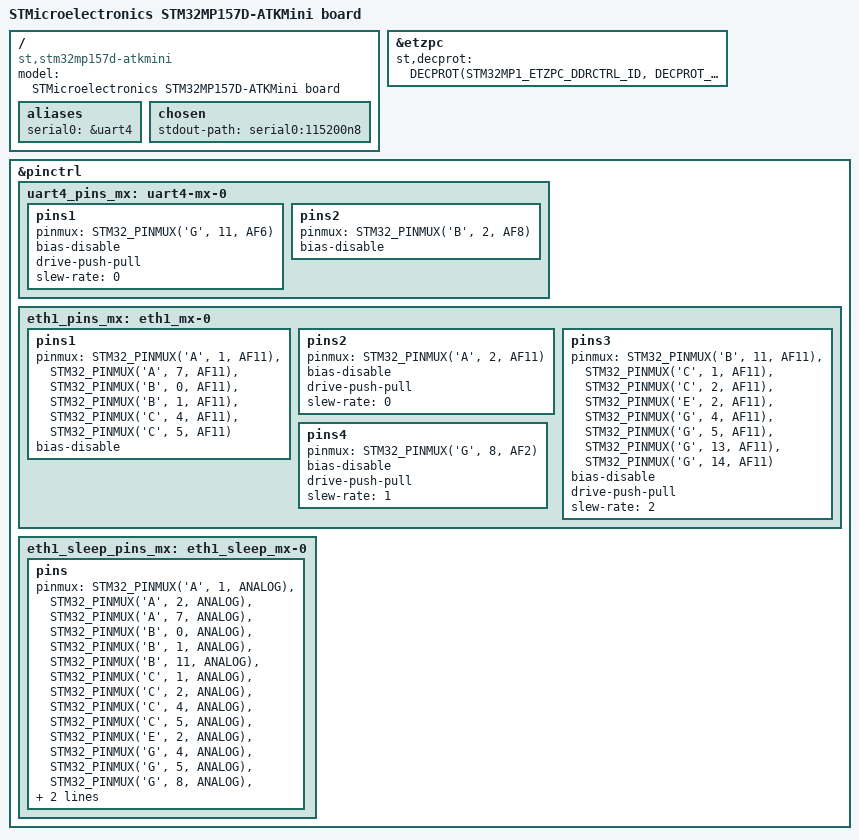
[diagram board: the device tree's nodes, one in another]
// SPDX-License-Identifier: (GPL-2.0+ OR BSD-3-Clause)
/*
 * Copyright (C) STMicroelectronics 2019 - All Rights Reserved
 * Author: Alexandre Torgue <alexandre.torgue@st.com> for STMicroelectronics.
 */
/dts-v1/;

#include "stm32mp157.dtsi"
#include "stm32mp15xd.dtsi"
#include "stm32mp15-pinctrl.dtsi"
#include "stm32mp15xxaa-pinctrl.dtsi"
#include "stm32mp157d-atkmini.dtsi"
#include <dt-bindings/soc/st,stm32-etzpc.h>

/ {
	model = "STMicroelectronics STM32MP157D-ATKMini board";
	compatible = "st,stm32mp157d-atkmini", "st,stm32mp157";

	aliases {
		serial0 = &uart4;
	};

	chosen {
		stdout-path = "serial0:115200n8";
	};
};

&etzpc {
	st,decprot = <
		/*"NS_R S_W" peripherals*/
		DECPROT(STM32MP1_ETZPC_DDRCTRL_ID, DECPROT_NS_R_S_W, DECPROT_LOCK)
		DECPROT(STM32MP1_ETZPC_DDRPHYC_ID, DECPROT_NS_R_S_W, DECPROT_LOCK)
		/*"Non Secured" peripherals*/
		DECPROT(STM32MP1_ETZPC_DMA1_ID, DECPROT_NS_RW, DECPROT_UNLOCK)
		DECPROT(STM32MP1_ETZPC_DMAMUX_ID, DECPROT_NS_RW, DECPROT_UNLOCK)
		DECPROT(STM32MP1_ETZPC_ETH_ID, DECPROT_NS_RW, DECPROT_UNLOCK)
		DECPROT(STM32MP1_ETZPC_UART4_ID, DECPROT_NS_RW, DECPROT_UNLOCK)
		/*"Secured" peripherals*/
		DECPROT(STM32MP1_ETZPC_STGENC_ID, DECPROT_S_RW, DECPROT_UNLOCK)
		/*"Mcu Isolation" peripherals*/
		DECPROT(STM32MP1_ETZPC_DMA2_ID, DECPROT_MCU_ISOLATION, DECPROT_UNLOCK)
	>;
};

&pinctrl {
	uart4_pins_mx: uart4-mx-0 {
		pins1 {
			pinmux = <STM32_PINMUX('G', 11, AF6)>; /* UART4_TX */
			bias-disable;
			drive-push-pull;
			slew-rate = <0>;
		};
		pins2 {
			pinmux = <STM32_PINMUX('B', 2, AF8)>; /* UART4_RX */
			bias-disable;
		};
	};

	eth1_pins_mx: eth1_mx-0 {
		pins1 {
			pinmux = <STM32_PINMUX('A', 1, AF11)>, /* ETH1_RX_CLK */
					 <STM32_PINMUX('A', 7, AF11)>, /* ETH1_RX_CTL */
					 <STM32_PINMUX('B', 0, AF11)>, /* ETH1_RXD2 */
					 <STM32_PINMUX('B', 1, AF11)>, /* ETH1_RXD3 */
					 <STM32_PINMUX('C', 4, AF11)>, /* ETH1_RXD0 */
					 <STM32_PINMUX('C', 5, AF11)>; /* ETH1_RXD1 */
			bias-disable;
		};
		pins2 {
			pinmux = <STM32_PINMUX('A', 2, AF11)>; /* ETH1_MDIO */
			bias-disable;
			drive-push-pull;
			slew-rate = <0>;
		};
		pins3 {
			pinmux = <STM32_PINMUX('B', 11, AF11)>, /* ETH1_TX_CTL */
					 <STM32_PINMUX('C', 1, AF11)>, /* ETH1_MDC */
					 <STM32_PINMUX('C', 2, AF11)>, /* ETH1_TXD2 */
					 <STM32_PINMUX('E', 2, AF11)>, /* ETH1_TXD3 */
					 <STM32_PINMUX('G', 4, AF11)>, /* ETH1_GTX_CLK */
					 <STM32_PINMUX('G', 5, AF11)>, /* ETH1_CLK125 */
					 <STM32_PINMUX('G', 13, AF11)>, /* ETH1_TXD0 */
					 <STM32_PINMUX('G', 14, AF11)>; /* ETH1_TXD1 */
			bias-disable;
			drive-push-pull;
			slew-rate = <2>;
		};
		pins4 {
			pinmux = <STM32_PINMUX('G', 8, AF2)>; /* ETH1_CLK */
			bias-disable;
			drive-push-pull;
			slew-rate = <1>;
		};
	};

	eth1_sleep_pins_mx: eth1_sleep_mx-0 {
		pins {
			pinmux = <STM32_PINMUX('A', 1, ANALOG)>, /* ETH1_RX_CLK */
					 <STM32_PINMUX('A', 2, ANALOG)>, /* ETH1_MDIO */
					 <STM32_PINMUX('A', 7, ANALOG)>, /* ETH1_RX_CTL */
					 <STM32_PINMUX('B', 0, ANALOG)>, /* ETH1_RXD2 */
					 <STM32_PINMUX('B', 1, ANALOG)>, /* ETH1_RXD3 */
					 <STM32_PINMUX('B', 11, ANALOG)>, /* ETH1_TX_CTL */
					 <STM32_PINMUX('C', 1, ANALOG)>, /* ETH1_MDC */
					 <STM32_PINMUX('C', 2, ANALOG)>, /* ETH1_TXD2 */
					 <STM32_PINMUX('C', 4, ANALOG)>, /* ETH1_RXD0 */
					 <STM32_PINMUX('C', 5, ANALOG)>, /* ETH1_RXD1 */
					 <STM32_PINMUX('E', 2, ANALOG)>, /* ETH1_TXD3 */
					 <STM32_PINMUX('G', 4, ANALOG)>, /* ETH1_GTX_CLK */
					 <STM32_PINMUX('G', 5, ANALOG)>, /* ETH1_CLK125 */
					 <STM32_PINMUX('G', 8, ANALOG)>, /* ETH1_CLK */
					 <STM32_PINMUX('G', 13, ANALOG)>, /* ETH1_TXD0 */
					 <STM32_PINMUX('G', 14, ANALOG)>; /* ETH1_TXD1 */
		};
	};
};
